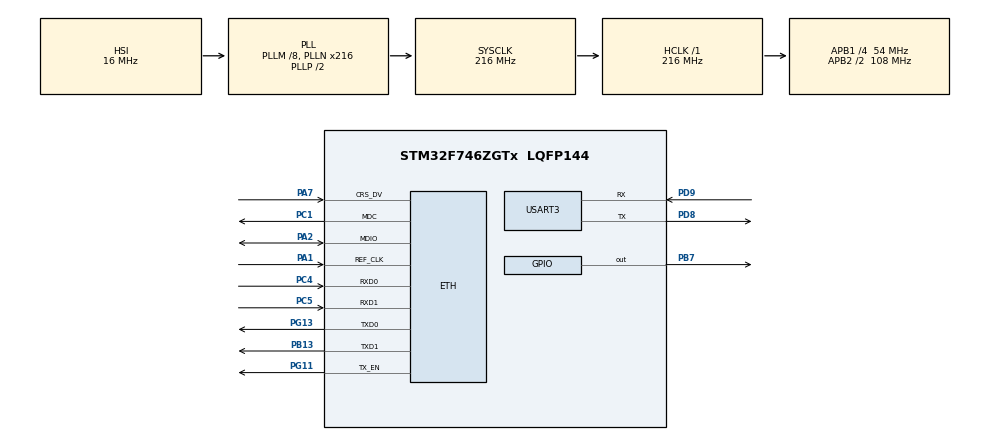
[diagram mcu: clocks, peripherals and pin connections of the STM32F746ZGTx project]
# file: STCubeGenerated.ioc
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ETH.MediaInterface=HAL_ETH_RMII_MODE
Mcu.Family=STM32F7
Mcu.Name=STM32F746ZGTx
Mcu.Package=LQFP144
NVIC.ETH_IRQn=true\:0\:0\:false\:false\:false\:true\:true\:true
NVIC.PriorityGroup=NVIC_PRIORITYGROUP_4
NVIC.TIM6_DAC_IRQn=true\:15\:0\:false\:false\:true\:false\:true\:true
NVIC.TimeBase=TIM6_DAC_IRQn
NVIC.TimeBaseIP=TIM6
PA1.Mode=RMII
PA1.Signal=ETH_REF_CLK
PA2.Mode=RMII
PA2.Signal=ETH_MDIO
PA7.Mode=RMII
PA7.Signal=ETH_CRS_DV
PB13.Mode=RMII
PB13.Signal=ETH_TXD1
PB7.Signal=GPIO_Output
PC1.Mode=RMII
PC1.Signal=ETH_MDC
PC4.Mode=RMII
PC4.Signal=ETH_RXD0
PC5.Mode=RMII
PC5.Signal=ETH_RXD1
PD8.Mode=Asynchronous
PD8.Signal=USART3_TX
PD9.Mode=Asynchronous
PD9.Signal=USART3_RX
PG11.Mode=RMII
PG11.Signal=ETH_TX_EN
PG13.Mode=RMII
PG13.Signal=ETH_TXD0
ProjectManager.HeapSize=0x200
ProjectManager.StackSize=0x400
ProjectManager.TargetToolchain=MDK-ARM V5
RCC.AHBFreq_Value=216000000
RCC.APB1CLKDivider=RCC_HCLK_DIV4
RCC.APB1Freq_Value=54000000
RCC.APB1TimFreq_Value=108000000
RCC.APB2CLKDivider=RCC_HCLK_DIV2
RCC.APB2Freq_Value=108000000
RCC.APB2TimFreq_Value=216000000
RCC.CortexFreq_Value=216000000
RCC.HCLKFreq_Value=216000000
RCC.HSE_VALUE=25000000
RCC.HSI_VALUE=16000000
RCC.LSE_VALUE=32768
RCC.PLLM=8
RCC.PLLN=216
RCC.PLLQ=9
RCC.SYSCLKFreq_VALUE=216000000
RCC.SYSCLKSource=RCC_SYSCLKSOURCE_PLLCLK
RCC.USBFreq_Value=48000000
RCC.VCOOutputFreq_Value=432000000
USART3.VirtualMode-Asynchronous=VM_ASYNC
VP_RNG_VS_RNG.Mode=RNG_Activate
VP_SYS_VS_tim6.Mode=TIM6
board=custom

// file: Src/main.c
/* USER CODE BEGIN Header */
/**
  ******************************************************************************
  * @file           : main.c
  * @brief          : Main program body
  ******************************************************************************
  * @attention
  *
  * Copyright (c) 2023 STMicroelectronics.
  * All rights reserved.
  *
  * This software is licensed under terms that can be found in the LICENSE file
  * in the root directory of this software component.
  * If no LICENSE file comes with this software, it is provided AS-IS.
  *
  ******************************************************************************
  */
/* USER CODE END Header */
#include "main.h"
#include "string.h"

/* USER CODE BEGIN Includes */
#include "cmsis_os2.h"

/* USER CODE END Includes */

#if defined ( __ICCARM__ ) /*!< IAR Compiler */
#pragma location=0x2004c000
ETH_DMADescTypeDef  DMARxDscrTab[ETH_RX_DESC_CNT]; /* Ethernet Rx DMA Descriptors */
#pragma location=0x2004c0a0
ETH_DMADescTypeDef  DMATxDscrTab[ETH_TX_DESC_CNT]; /* Ethernet Tx DMA Descriptors */

#elif defined ( __CC_ARM )  /* MDK ARM Compiler */

__attribute__((at(0x2004c000))) ETH_DMADescTypeDef  DMARxDscrTab[ETH_RX_DESC_CNT]; /* Ethernet Rx DMA Descriptors */
__attribute__((at(0x2004c0a0))) ETH_DMADescTypeDef  DMATxDscrTab[ETH_TX_DESC_CNT]; /* Ethernet Tx DMA Descriptors */

#elif defined ( __GNUC__ ) /* GNU Compiler */
ETH_DMADescTypeDef DMARxDscrTab[ETH_RX_DESC_CNT] __attribute__((section(".RxDecripSection"))); /* Ethernet Rx DMA Descriptors */
ETH_DMADescTypeDef DMATxDscrTab[ETH_TX_DESC_CNT] __attribute__((section(".TxDecripSection")));   /* Ethernet Tx DMA Descriptors */

#endif

ETH_TxPacketConfig TxConfig;

ETH_HandleTypeDef heth;

RNG_HandleTypeDef hrng;

UART_HandleTypeDef huart3;

void SystemClock_Config(void);
static void MX_GPIO_Init(void);
static void MX_USART3_UART_Init(void);
static void MX_ETH_Init(void);
static void MX_RNG_Init(void);

/* USER CODE BEGIN 0 */

void mx_init(void) {
  SystemClock_Config();
  MX_GPIO_Init();
  MX_USART3_UART_Init();
  MX_RNG_Init();
  MX_ETH_Init();
}

/* USER CODE END 0 */

void SystemClock_Config(void)
{
  RCC_OscInitTypeDef RCC_OscInitStruct = {0};
  RCC_ClkInitTypeDef RCC_ClkInitStruct = {0};

  /** Configure the main internal regulator output voltage
  */
  __HAL_RCC_PWR_CLK_ENABLE();
  __HAL_PWR_VOLTAGESCALING_CONFIG(PWR_REGULATOR_VOLTAGE_SCALE1);

  /** Initializes the RCC Oscillators according to the specified parameters
  * in the RCC_OscInitTypeDef structure.
  */
  RCC_OscInitStruct.OscillatorType = RCC_OSCILLATORTYPE_HSI;
  RCC_OscInitStruct.HSIState = RCC_HSI_ON;
  RCC_OscInitStruct.HSICalibrationValue = RCC_HSICALIBRATION_DEFAULT;
  RCC_OscInitStruct.PLL.PLLState = RCC_PLL_ON;
  RCC_OscInitStruct.PLL.PLLSource = RCC_PLLSOURCE_HSI;
  RCC_OscInitStruct.PLL.PLLM = 8;
  RCC_OscInitStruct.PLL.PLLN = 216;
  RCC_OscInitStruct.PLL.PLLP = RCC_PLLP_DIV2;
  RCC_OscInitStruct.PLL.PLLQ = 9;
  if (HAL_RCC_OscConfig(&RCC_OscInitStruct) != HAL_OK)
  {
    Error_Handler();
  }

  /** Activate the Over-Drive mode
  */
  if (HAL_PWREx_EnableOverDrive() != HAL_OK)
  {
    Error_Handler();
  }

  /** Initializes the CPU, AHB and APB buses clocks
  */
  RCC_ClkInitStruct.ClockType = RCC_CLOCKTYPE_HCLK|RCC_CLOCKTYPE_SYSCLK
                              |RCC_CLOCKTYPE_PCLK1|RCC_CLOCKTYPE_PCLK2;
  RCC_ClkInitStruct.SYSCLKSource = RCC_SYSCLKSOURCE_PLLCLK;
  RCC_ClkInitStruct.AHBCLKDivider = RCC_SYSCLK_DIV1;
  RCC_ClkInitStruct.APB1CLKDivider = RCC_HCLK_DIV4;
  RCC_ClkInitStruct.APB2CLKDivider = RCC_HCLK_DIV2;

  if (HAL_RCC_ClockConfig(&RCC_ClkInitStruct, FLASH_LATENCY_7) != HAL_OK)
  {
    Error_Handler();
  }
}

static void MX_ETH_Init(void)
{

   static uint8_t MACAddr[6];

  heth.Instance = ETH;
  MACAddr[0] = 0x00;
  MACAddr[1] = 0x80;
  MACAddr[2] = 0xE1;
  MACAddr[3] = 0x00;
  MACAddr[4] = 0x00;
  MACAddr[5] = 0x00;
  heth.Init.MACAddr = &MACAddr[0];
  heth.Init.MediaInterface = HAL_ETH_RMII_MODE;
  heth.Init.TxDesc = DMATxDscrTab;
  heth.Init.RxDesc = DMARxDscrTab;
  heth.Init.RxBuffLen = 1524;

  if (HAL_ETH_Init(&heth) != HAL_OK)
  {
    Error_Handler();
  }

  memset(&TxConfig, 0 , sizeof(ETH_TxPacketConfig));
  TxConfig.Attributes = ETH_TX_PACKETS_FEATURES_CSUM | ETH_TX_PACKETS_FEATURES_CRCPAD;
  TxConfig.ChecksumCtrl = ETH_CHECKSUM_IPHDR_PAYLOAD_INSERT_PHDR_CALC;
  TxConfig.CRCPadCtrl = ETH_CRC_PAD_INSERT;

}

static void MX_RNG_Init(void)
{

  hrng.Instance = RNG;
  if (HAL_RNG_Init(&hrng) != HAL_OK)
  {
    Error_Handler();
  }

}

static void MX_USART3_UART_Init(void)
{

  huart3.Instance = USART3;
  huart3.Init.BaudRate = 115200;
  huart3.Init.WordLength = UART_WORDLENGTH_8B;
  huart3.Init.StopBits = UART_STOPBITS_1;
  huart3.Init.Parity = UART_PARITY_NONE;
  huart3.Init.Mode = UART_MODE_TX_RX;
  huart3.Init.HwFlowCtl = UART_HWCONTROL_NONE;
  huart3.Init.OverSampling = UART_OVERSAMPLING_16;
  huart3.Init.OneBitSampling = UART_ONE_BIT_SAMPLE_DISABLE;
  huart3.AdvancedInit.AdvFeatureInit = UART_ADVFEATURE_NO_INIT;
  if (HAL_UART_Init(&huart3) != HAL_OK)
  {
    Error_Handler();
  }

}

static void MX_GPIO_Init(void)
{
  GPIO_InitTypeDef GPIO_InitStruct = {0};

  /* GPIO Ports Clock Enable */
  __HAL_RCC_GPIOC_CLK_ENABLE();
  __HAL_RCC_GPIOA_CLK_ENABLE();
  __HAL_RCC_GPIOB_CLK_ENABLE();
  __HAL_RCC_GPIOD_CLK_ENABLE();
  __HAL_RCC_GPIOG_CLK_ENABLE();

  /*Configure GPIO pin Output Level */
  HAL_GPIO_WritePin(GPIOB, GPIO_PIN_7, GPIO_PIN_RESET);

  /*Configure GPIO pin : PB7 */
  GPIO_InitStruct.Pin = GPIO_PIN_7;
  GPIO_InitStruct.Mode = GPIO_MODE_OUTPUT_PP;
  GPIO_InitStruct.Pull = GPIO_NOPULL;
  GPIO_InitStruct.Speed = GPIO_SPEED_FREQ_LOW;
  HAL_GPIO_Init(GPIOB, &GPIO_InitStruct);

}

void HAL_TIM_PeriodElapsedCallback(TIM_HandleTypeDef *htim)
{
  if (htim->Instance == TIM6) {
    HAL_IncTick();
  }
}

void Error_Handler(void)
{
  __disable_irq();
  while (1)
  {
  }
}
